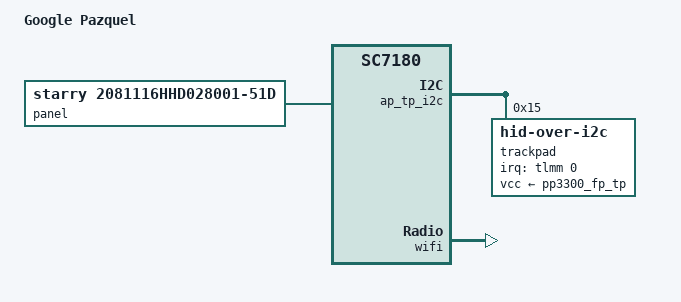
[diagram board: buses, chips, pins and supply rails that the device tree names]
// SPDX-License-Identifier: (GPL-2.0+ OR MIT)
/*
 * Google Pazquel board device tree source
 *
 * Copyright 2021 Google LLC.
 */

/dts-v1/;

#include "sc7180.dtsi"

ap_ec_spi: &spi6 {};
ap_h1_spi: &spi0 {};

#include "sc7180-trogdor.dtsi"

/ {
	model = "Google Pazquel";
	compatible = "google,pazquel", "qcom,sc7180";
};

/delete-node/&trackpad;
&ap_tp_i2c {
	trackpad: trackpad@15 {
		compatible = "hid-over-i2c";
		reg = <0x15>;
		pinctrl-names = "default";
		pinctrl-0 = <&tp_int_odl>;

		interrupt-parent = <&tlmm>;
		interrupts = <0 IRQ_TYPE_EDGE_FALLING>;

		vcc-supply = <&pp3300_fp_tp>;
		post-power-on-delay-ms = <100>;
		hid-descr-addr = <0x0001>;

		wakeup-source;
	};
};

&panel {
	compatible = "starry,2081116HHD028001-51D", "kingdisplay,kd116n21-30nv-a010";
};

&pp3300_dx_edp {
	gpio = <&tlmm 67 GPIO_ACTIVE_HIGH>;
};

&en_pp3300_dx_edp {
	pinmux {
		pins = "gpio67";
	};

	pinconf {
		pins = "gpio67";
	};
};

&wifi {
	qcom,ath10k-calibration-variant = "GO_PAZQUEL";
};

/* PINCTRL - board-specific pinctrl */

&tlmm {
	gpio-line-names = "TP_INT_ODL",
			  "AP_RAM_ID0",
			  "AP_SKU_ID2",
			  "AP_RAM_ID1",
			  "",
			  "AP_RAM_ID2",
			  "AP_TP_I2C_SDA",
			  "AP_TP_I2C_SCL",
			  "TS_RESET_L",
			  "TS_INT_L",
			  "",
			  "EDP_BRIJ_IRQ",
			  "AP_EDP_BKLTEN",
			  "",
			  "",
			  "EDP_BRIJ_I2C_SDA",
			  "EDP_BRIJ_I2C_SCL",
			  "HUB_RST_L",
			  "",
			  "",
			  "",
			  "",
			  "",
			  "AMP_EN",
			  "P_SENSOR_INT_L",
			  "AP_SAR_SENSOR_SDA",
			  "AP_SAR_SENSOR_SCL",
			  "",
			  "HP_IRQ",
			  "",
			  "",
			  "AP_BRD_ID2",
			  "BRIJ_SUSPEND",
			  "AP_BRD_ID0",
			  "AP_H1_SPI_MISO",
			  "AP_H1_SPI_MOSI",
			  "AP_H1_SPI_CLK",
			  "AP_H1_SPI_CS_L",
			  "",
			  "",
			  "",
			  "",
			  "H1_AP_INT_ODL",
			  "",
			  "UART_AP_TX_DBG_RX",
			  "UART_DBG_TX_AP_RX",
			  "HP_I2C_SDA",
			  "HP_I2C_SCL",
			  "FORCED_USB_BOOT",
			  "AMP_BCLK",
			  "AMP_LRCLK",
			  "AMP_DIN",
			  "",
			  "HP_BCLK",
			  "HP_LRCLK",
			  "HP_DOUT",
			  "HP_DIN",
			  "HP_MCLK",
			  "AP_SKU_ID0",
			  "AP_EC_SPI_MISO",
			  "AP_EC_SPI_MOSI",
			  "AP_EC_SPI_CLK",
			  "AP_EC_SPI_CS_L",
			  "AP_SPI_CLK",
			  "AP_SPI_MOSI",
			  "AP_SPI_MISO",
			  /*
			   * AP_FLASH_WP_L is crossystem ABI. Schematics
			   * call it BIOS_FLASH_WP_L.
			   */
			  "AP_FLASH_WP_L",
			  "EN_PP3300_DX_EDP",
			  "AP_SPI_CS0_L",
			  "",
			  "",
			  "",
			  "",
			  "",
			  "",
			  "UIM2_DATA",
			  "UIM2_CLK",
			  "UIM2_RST",
			  "UIM2_PRESENT",
			  "UIM1_DATA",
			  "UIM1_CLK",
			  "UIM1_RST",
			  "",
			  "CODEC_PWR_EN",
			  "HUB_EN",
			  "",
			  "",
			  "",
			  "",
			  "",
			  "AP_SKU_ID1",
			  "AP_RST_REQ",
			  "",
			  "AP_BRD_ID1",
			  "AP_EC_INT_L",
			  "",
			  "",
			  "",
			  "",
			  "",
			  "",
			  "",
			  "",
			  "",
			  "EDP_BRIJ_EN",
			  "",
			  "",
			  "",
			  "",
			  "",
			  "",
			  "",
			  "",
			  "",
			  "",
			  "AP_TS_PEN_I2C_SDA",
			  "AP_TS_PEN_I2C_SCL",
			  "DP_HOT_PLUG_DET",
			  "EC_IN_RW_ODL";
};
